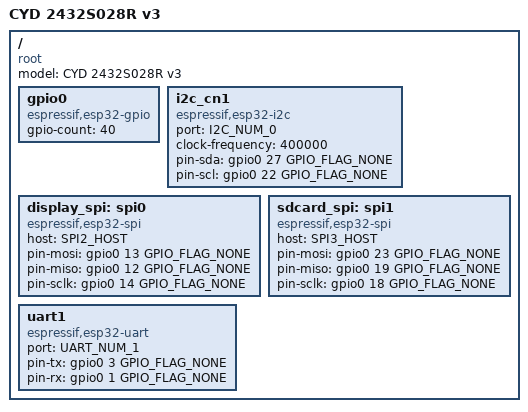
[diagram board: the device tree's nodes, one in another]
/dts-v1/;

#include <tactility/bindings/root.h>
#include <tactility/bindings/esp32_gpio.h>
#include <tactility/bindings/esp32_i2c.h>
#include <tactility/bindings/esp32_uart.h>
#include <tactility/bindings/esp32_spi.h>

/ {
	compatible = "root";
	model = "CYD 2432S028R v3";

	gpio0 {
		compatible = "espressif,esp32-gpio";
		gpio-count = <40>;
	};

	i2c_cn1 {
		compatible = "espressif,esp32-i2c";
		port = <I2C_NUM_0>;
		clock-frequency = <400000>;
		pin-sda = <&gpio0 27 GPIO_FLAG_NONE>;
		pin-scl = <&gpio0 22 GPIO_FLAG_NONE>;
	};

	display_spi: spi0 {
		compatible = "espressif,esp32-spi";
		host = <SPI2_HOST>;
		pin-mosi = <&gpio0 13 GPIO_FLAG_NONE>;
		pin-miso = <&gpio0 12 GPIO_FLAG_NONE>;
		pin-sclk = <&gpio0 14 GPIO_FLAG_NONE>;
	};

	sdcard_spi: spi1 {
		compatible = "espressif,esp32-spi";
		host = <SPI3_HOST>;
		pin-mosi = <&gpio0 23 GPIO_FLAG_NONE>;
		pin-miso = <&gpio0 19 GPIO_FLAG_NONE>;
		pin-sclk = <&gpio0 18 GPIO_FLAG_NONE>;
	};

	uart1 {
		compatible = "espressif,esp32-uart";
		port = <UART_NUM_1>;
		pin-tx = <&gpio0 3 GPIO_FLAG_NONE>;
		pin-rx = <&gpio0 1 GPIO_FLAG_NONE>;
	};
};
